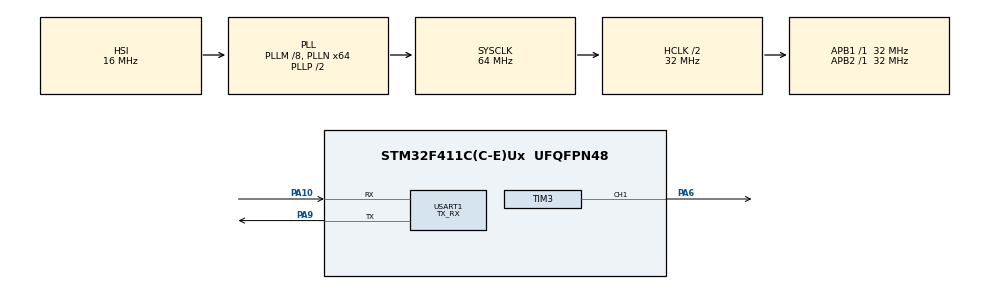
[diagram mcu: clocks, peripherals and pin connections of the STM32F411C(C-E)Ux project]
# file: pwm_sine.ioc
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Mcu.Family=STM32F4
Mcu.Name=STM32F411C(C-E)Ux
Mcu.Package=UFQFPN48
NVIC.PriorityGroup=NVIC_PRIORITYGROUP_4
NVIC.TIM3_IRQn=true\:0\:0\:false\:false\:true\:true\:true\:true
NVIC.USART1_IRQn=true\:0\:0\:false\:false\:true\:true\:true\:true
PA10.Mode=Asynchronous
PA10.Signal=USART1_RX
PA6.Signal=S_TIM3_CH1
PA9.Mode=Asynchronous
PA9.Signal=USART1_TX
ProjectManager.HeapSize=0x200
ProjectManager.StackSize=0x400
ProjectManager.TargetToolchain=STM32CubeIDE
RCC.48MHZClocksFreq_Value=32000000
RCC.AHBCLKDivider=RCC_SYSCLK_DIV2
RCC.AHBFreq_Value=32000000
RCC.APB1Freq_Value=32000000
RCC.APB1TimFreq_Value=32000000
RCC.APB2Freq_Value=32000000
RCC.APB2TimFreq_Value=32000000
RCC.CortexFreq_Value=32000000
RCC.HCLKFreq_Value=32000000
RCC.HSE_VALUE=25000000
RCC.HSI_VALUE=16000000
RCC.LSE_VALUE=32768
RCC.PLLM=8
RCC.PLLN=64
RCC.SYSCLKFreq_VALUE=64000000
RCC.SYSCLKSource=RCC_SYSCLKSOURCE_PLLCLK
RCC.VCOOutputFreq_Value=128000000
SH.S_TIM3_CH1.0=TIM3_CH1,PWM Generation1 CH1
TIM3.Channel-PWM\ Generation1\ CH1=TIM_CHANNEL_1
TIM3.Period=1000-1
TIM3.Prescaler=1-1
USART1.Mode=MODE_TX_RX
USART1.VirtualMode=VM_ASYNC
VP_TIM3_VS_ClockSourceINT.Mode=Internal
board=custom

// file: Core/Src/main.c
/* USER CODE BEGIN Header */
/**
  ******************************************************************************
  * @file           : main.c
  * @brief          : Main program body
  ******************************************************************************
  * @attention
  *
  * Copyright (c) 2026 STMicroelectronics.
  * All rights reserved.
  *
  * This software is licensed under terms that can be found in the LICENSE file
  * in the root directory of this software component.
  * If no LICENSE file comes with this software, it is provided AS-IS.
  *
  ******************************************************************************
  */
/* USER CODE END Header */
#include "main.h"

/* USER CODE BEGIN Includes */
#include <math.h>		// Math functions (sine, etc.)
#include <stdlib.h>		// atof()
#include <string.h>		// memset()

/* USER CODE END Includes */

/* USER CODE BEGIN PD */
#define PI 3.14159
#define LUT_SIZE 1000			// Number of samples in the sine lookup table
#define RX_BUFFER_SIZE 10		// UART receive buffer size
#define F_UPDATE 32000.0f		// Timer interrupt frequency (update rate)
/* USER CODE END PD */

TIM_HandleTypeDef htim3;
UART_HandleTypeDef huart1;

void SystemClock_Config(void);
static void MX_GPIO_Init(void);
static void MX_TIM3_Init(void);
static void MX_USART1_UART_Init(void);

/* USER CODE BEGIN 0 */

uint16_t sine_lut[LUT_SIZE];		// Sine lookup table (stores duty cycle values)
uint8_t rx_data;                   	// Single received byte
char rx_buffer[RX_BUFFER_SIZE];    	// Buffer to store received string
uint8_t rx_index = 0;              	// Current position in buffer
volatile float step = 1.0;         	// Step size controls output frequency
float index_f = 0;                 	// Floating index for LUT traversal

void HAL_UART_RxCpltCallback(UART_HandleTypeDef *huart)
{
    if (huart->Instance == USART1)
    {
        char c = rx_data;

        if (c == '\n' || c == '\r')		// Check for end of command (newline or carriage return)
        {
            if (rx_index > 0)
            {
            	rx_buffer[rx_index] = '\0';			// Null-terminate string
            	float freq = atof(rx_buffer);		// Convert received string to float (frequency)

            	// Clamp frequency between 20 Hz and 200 Hz
                if (freq < 20.0) freq = 20.0;
                if (freq > 200.0) freq = 200.0;

                step = (freq * LUT_SIZE) / F_UPDATE; // Calculate DDS step based on desired frequency

            }
            // Reset buffer for next command
            rx_index = 0;
            memset(rx_buffer, 0, RX_BUFFER_SIZE);
        }
        else
        {
        	// Store received character if buffer is not full
            if (rx_index < RX_BUFFER_SIZE - 1)
            {
                rx_buffer[rx_index++] = c;
            }
        }

        HAL_UART_Receive_IT(&huart1, &rx_data, 1);
    }
}

void HAL_TIM_PeriodElapsedCallback(TIM_HandleTypeDef *htim)
{
    if (htim->Instance == TIM3)
    {
    	// Increment LUT index using DDS step
    	index_f += step;

    	// Wrap around LUT index
    	while (index_f >= LUT_SIZE) index_f -= LUT_SIZE;

    	// Update PWM duty cycle using LUT value
    	__HAL_TIM_SET_COMPARE(&htim3, TIM_CHANNEL_1, sine_lut[(uint16_t)index_f]);
    }
}
/* USER CODE END 0 */

int main(void)
{

  /* MCU Configuration--------------------------------------------------------*/

  /* Reset of all peripherals, Initializes the Flash interface and the Systick. */
  HAL_Init();

  /* Configure the system clock */
  SystemClock_Config();

  /* Initialize all configured peripherals */
  MX_GPIO_Init();
  MX_TIM3_Init();
  MX_USART1_UART_Init();
  /* USER CODE BEGIN 2 */

  // Generate sine lookup table
  for (int i = 0; i < LUT_SIZE; i++)
  {
	  float angle = (2 * PI * i) / LUT_SIZE;	// Compute angle
	  float sine = (sinf(angle) + 1.0) / 2.0; 	// Normalize to range [0, 1]

	  sine_lut[i] = (uint16_t)(sine * 1000); 	// Scale to PWM range (based on ARR value)
   }

  HAL_UART_Receive_IT(&huart1, &rx_data, 1);
  HAL_TIM_Base_Start_IT(&htim3);     // habilita interrupção
  HAL_TIM_PWM_Start(&htim3, TIM_CHANNEL_1); // liga PWM

  /* USER CODE END 2 */

  /* Infinite loop */
  while (1)
  {

  }
}

void SystemClock_Config(void)
{
  RCC_OscInitTypeDef RCC_OscInitStruct = {0};
  RCC_ClkInitTypeDef RCC_ClkInitStruct = {0};

  /** Configure the main internal regulator output voltage
  */
  __HAL_RCC_PWR_CLK_ENABLE();
  __HAL_PWR_VOLTAGESCALING_CONFIG(PWR_REGULATOR_VOLTAGE_SCALE1);

  /** Initializes the RCC Oscillators according to the specified parameters
  * in the RCC_OscInitTypeDef structure.
  */
  RCC_OscInitStruct.OscillatorType = RCC_OSCILLATORTYPE_HSI;
  RCC_OscInitStruct.HSIState = RCC_HSI_ON;
  RCC_OscInitStruct.HSICalibrationValue = RCC_HSICALIBRATION_DEFAULT;
  RCC_OscInitStruct.PLL.PLLState = RCC_PLL_ON;
  RCC_OscInitStruct.PLL.PLLSource = RCC_PLLSOURCE_HSI;
  RCC_OscInitStruct.PLL.PLLM = 8;
  RCC_OscInitStruct.PLL.PLLN = 64;
  RCC_OscInitStruct.PLL.PLLP = RCC_PLLP_DIV2;
  RCC_OscInitStruct.PLL.PLLQ = 4;
  if (HAL_RCC_OscConfig(&RCC_OscInitStruct) != HAL_OK)
  {
    Error_Handler();
  }

  /** Initializes the CPU, AHB and APB buses clocks
  */
  RCC_ClkInitStruct.ClockType = RCC_CLOCKTYPE_HCLK|RCC_CLOCKTYPE_SYSCLK
                              |RCC_CLOCKTYPE_PCLK1|RCC_CLOCKTYPE_PCLK2;
  RCC_ClkInitStruct.SYSCLKSource = RCC_SYSCLKSOURCE_PLLCLK;
  RCC_ClkInitStruct.AHBCLKDivider = RCC_SYSCLK_DIV2;
  RCC_ClkInitStruct.APB1CLKDivider = RCC_HCLK_DIV1;
  RCC_ClkInitStruct.APB2CLKDivider = RCC_HCLK_DIV1;

  if (HAL_RCC_ClockConfig(&RCC_ClkInitStruct, FLASH_LATENCY_1) != HAL_OK)
  {
    Error_Handler();
  }
}

static void MX_TIM3_Init(void)
{

  TIM_ClockConfigTypeDef sClockSourceConfig = {0};
  TIM_MasterConfigTypeDef sMasterConfig = {0};
  TIM_OC_InitTypeDef sConfigOC = {0};

  htim3.Instance = TIM3;
  htim3.Init.Prescaler = 1-1;
  htim3.Init.CounterMode = TIM_COUNTERMODE_UP;
  htim3.Init.Period = 1000-1;
  htim3.Init.ClockDivision = TIM_CLOCKDIVISION_DIV1;
  htim3.Init.AutoReloadPreload = TIM_AUTORELOAD_PRELOAD_DISABLE;
  if (HAL_TIM_Base_Init(&htim3) != HAL_OK)
  {
    Error_Handler();
  }
  sClockSourceConfig.ClockSource = TIM_CLOCKSOURCE_INTERNAL;
  if (HAL_TIM_ConfigClockSource(&htim3, &sClockSourceConfig) != HAL_OK)
  {
    Error_Handler();
  }
  if (HAL_TIM_PWM_Init(&htim3) != HAL_OK)
  {
    Error_Handler();
  }
  sMasterConfig.MasterOutputTrigger = TIM_TRGO_RESET;
  sMasterConfig.MasterSlaveMode = TIM_MASTERSLAVEMODE_DISABLE;
  if (HAL_TIMEx_MasterConfigSynchronization(&htim3, &sMasterConfig) != HAL_OK)
  {
    Error_Handler();
  }
  sConfigOC.OCMode = TIM_OCMODE_PWM1;
  sConfigOC.Pulse = 0;
  sConfigOC.OCPolarity = TIM_OCPOLARITY_HIGH;
  sConfigOC.OCFastMode = TIM_OCFAST_DISABLE;
  if (HAL_TIM_PWM_ConfigChannel(&htim3, &sConfigOC, TIM_CHANNEL_1) != HAL_OK)
  {
    Error_Handler();
  }
  HAL_TIM_MspPostInit(&htim3);

}

static void MX_USART1_UART_Init(void)
{

  huart1.Instance = USART1;
  huart1.Init.BaudRate = 115200;
  huart1.Init.WordLength = UART_WORDLENGTH_8B;
  huart1.Init.StopBits = UART_STOPBITS_1;
  huart1.Init.Parity = UART_PARITY_NONE;
  huart1.Init.Mode = UART_MODE_TX_RX;
  huart1.Init.HwFlowCtl = UART_HWCONTROL_NONE;
  huart1.Init.OverSampling = UART_OVERSAMPLING_16;
  if (HAL_UART_Init(&huart1) != HAL_OK)
  {
    Error_Handler();
  }

}

static void MX_GPIO_Init(void)
{

  /* GPIO Ports Clock Enable */
  __HAL_RCC_GPIOA_CLK_ENABLE();

}

void Error_Handler(void)
{
  __disable_irq();
  while (1)
  {
  }
}
